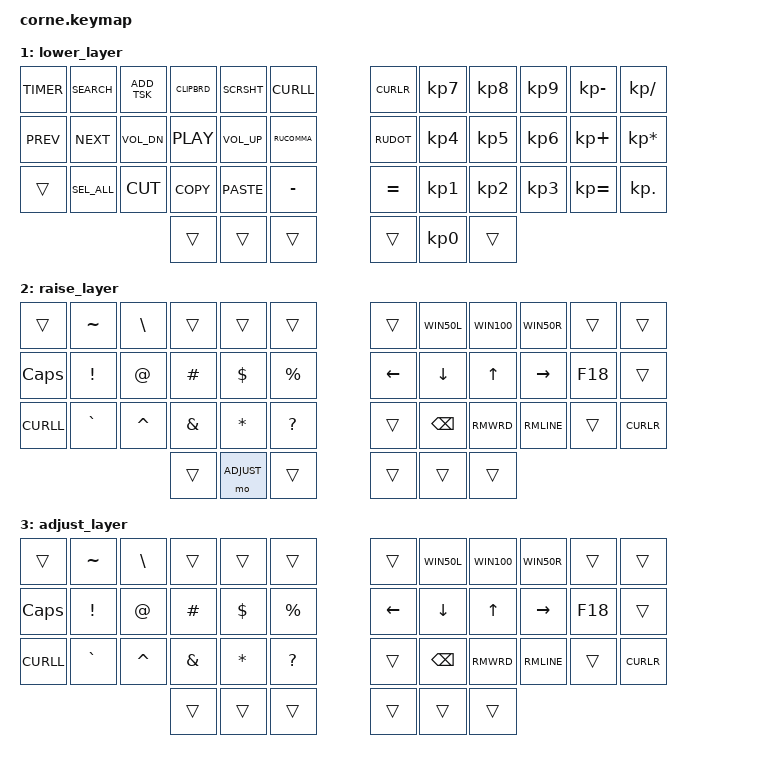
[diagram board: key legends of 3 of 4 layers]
/*
 * Copyright (c) 2020 The ZMK Contributors
 *
 * SPDX-License-Identifier: MIT
 */

#include <behaviors.dtsi>
#include <dt-bindings/zmk/keys.h>
#include <dt-bindings/zmk/bt.h>



// Layer shortcuts
#define QWERTY 0
#define LOWER 1
#define RAISE 2
#define ADJUST 3

// Window management via Magnet app
#define WIN50L LC(LA(LEFT))
#define WIN50R LC(LA(RIGHT))
#define WIN33L LC(LA(D))
#define WIN66R LC(LA(T))
#define WIN100 LC(LA(ENTER))

// Misc mac shortcuts
#define ALFRED LG(SPACE) // Toggle Alfred
#define SEARCH LS(LG((T))) // Fire Safafi with search engine
#define ADD_TSK LC(LS(LA(LG(A)))) // Add task via Todoist
#define CLIPBRD LC(LS(LA(LG(J)))) // Show Alfred clipboard
#define SCRSHT LS(LG((N4))) // Make a screenshot
#define TIMER LC(LS(LA(LG(T)))) // Toggle Tyme2
#define TERMINAL LC(F18) // Toggle Terminal
#define SAFARI LA(F18) // Toggle Safari

// Player shortcuts
#define PREV C_PREVIOUS
#define NEXT C_NEXT
#define VOL_DN C_VOLUME_DOWN
#define VOL_UP C_VOLUME_UP
#define PLAY C_PLAY_PAUSE

// Copy, paste etc
#define SEL_ALL LG(A)
#define CUT LG(B)
#define COPY LG(I)
#define PASTE LG(DOT)
#define RMWRD LA(BACKSPACE)
#define RMLINE LG(BACKSPACE)


// Brackets and punctuation
#define CURLL LS(MINUS)
#define CURLR LS(EQUAL)
#define RUCOMMA LS(N6)
#define RUDOT LS(N7)

/ {

    behaviors {
        hm: homerow_mods {
            compatible = "zmk,behavior-hold-tap";
            label = "HOMEROW_MODS";
            #binding-cells = <2>;
            tapping-term-ms = <200>;
            quick-tap-ms = <0>;
            flavor = "tap-preferred";
            bindings = <&kp>, <&kp>;
    };
        };

     keymap {
                compatible = "zmk,keymap";

                default_layer {
                        bindings = <
   &kp ESC   &kp Q &kp W &kp E &kp R &kp T   &kp Y &kp U  &kp I     &kp O   &kp P    &kp LEFT_BRACKET
   &mt &caps_word TAB &hm LCTRL A &hm LALT S &hm LGUI D &hm LSHIFT F &kp G   &kp H &hm LSHIFT J  &hm LGUI K &hm LALT L &hm LCTRL SEMI &kp SQT
   &mt LSHFT LPAR &kp Z &kp X &kp C &kp V &kp B   &kp N &kp M  &kp COMMA &kp DOT &kp FSLH &mt RSHFT RPAR
                  &caps_word &lt LOWER ALFRED &kp RET   &kp SPACE &mo RAISE &kp SAFARI
                        >;
                };

                lower_layer {
                        bindings = <
&kp TIMER   &kp SEARCH   &kp ADD_TSK   &kp CLIPBRD   &kp SCRSHT   &kp CURLL   &kp CURLR   &kp KP_N7   &kp KP_N8   &kp KP_N9   &kp KP_MINUS   &kp KP_SLASH
&kp PREV   &kp NEXT   &kp VOL_DN   &kp PLAY   &kp VOL_UP   &kp RUCOMMA   &kp RUDOT   &kp KP_N4   &kp KP_N5   &kp KP_N6   &kp KP_PLUS   &kp KP_ASTERISK
&trans   &kp SEL_ALL   &kp CUT   &kp COPY   &kp PASTE   &kp MINUS   &kp EQUAL   &kp KP_N1   &kp KP_N2   &kp KP_N3   &kp KP_EQUAL   &kp KP_DOT
       &trans   &trans   &trans   &trans   &kp KP_N0   &trans 
                        >;
                };

                raise_layer {
                        bindings = <
&trans   &kp TILDE   &kp BACKSLASH   &trans   &trans   &trans   &trans   &kp WIN50L   &kp WIN100   &kp WIN50R   &trans   &trans
&kp CAPSLOCK   &kp EXCLAMATION   &kp AT   &kp HASH   &kp DOLLAR   &kp PERCENT   &kp LEFT   &kp DOWN   &kp UP   &kp RIGHT   &kp F18   &trans
&kp CURLL   &kp GRAVE   &kp CARET   &kp AMPERSAND   &kp ASTERISK   &kp QUESTION   &trans   &kp BACKSPACE   &kp RMWRD   &kp RMLINE   &trans   &kp CURLR
             &trans   &mo ADJUST   &trans   &trans   &trans   &trans
                        >;
                };

                adjust_layer {
                        bindings = <
&trans   &kp TILDE   &kp BACKSLASH   &trans   &trans   &trans   &trans   &kp WIN50L   &kp WIN100   &kp WIN50R   &trans   &trans
&kp CAPSLOCK   &kp EXCLAMATION   &kp AT   &kp HASH   &kp DOLLAR   &kp PERCENT   &kp LEFT   &kp DOWN   &kp UP   &kp RIGHT   &kp F18   &trans
&kp CURLL   &kp GRAVE   &kp CARET   &kp AMPERSAND   &kp ASTERISK   &kp QUESTION   &trans   &kp BACKSPACE   &kp RMWRD   &kp RMLINE   &trans   &kp CURLR
             &trans   &trans   &trans   &trans   &trans   &trans
                        >;
                };
            
        };
};
